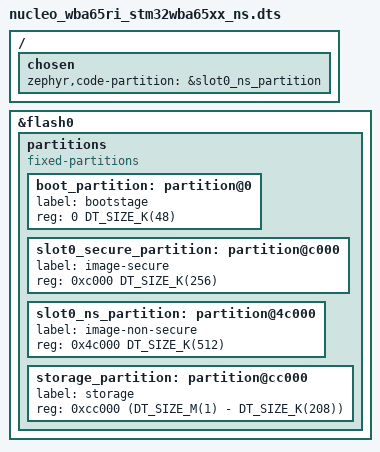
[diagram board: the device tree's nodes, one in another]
/*
 * Copyright (c) 2025 STMicroelectronics
 *
 * SPDX-License-Identifier: Apache-2.0
 */

/dts-v1/;
#include "nucleo_wba65ri.dts"

/ {
	chosen {
		zephyr,code-partition = &slot0_ns_partition;
	};
};


&flash0 {
	/delete-node/ partitions;

	partitions {
		compatible = "fixed-partitions";
		#address-cells = <1>;
		#size-cells = <1>;

		boot_partition: partition@0 {
			label = "bootstage";
			reg = <0 DT_SIZE_K(48)>;
		};

		slot0_secure_partition: partition@c000 {
			label = "image-secure";
			reg = <0xc000 DT_SIZE_K(256)>;
		};

		slot0_ns_partition: partition@4c000 {
			label = "image-non-secure";
			reg = <0x4c000 DT_SIZE_K(512)>;
		};

		storage_partition: partition@cc000 {
			label = "storage";
			reg = <0xcc000 (DT_SIZE_M(1) - DT_SIZE_K(208))>;
		};
	};
};
